# ATmega16U4 register map
Vendor: Atmel; File version: 1.0
CPU: other r0p0, little endian, no MPU, no FPU, 4 interrupt priority bits
Registers are 8-bit, read-write, reset 0x0 unless marked. A register's access mark holds for its fields unless they carry their own. Offsets are from the block's base; [hi:lo] are bit positions.

## TC3 — Timer/Counter, 16-bit
Base 0x00800038
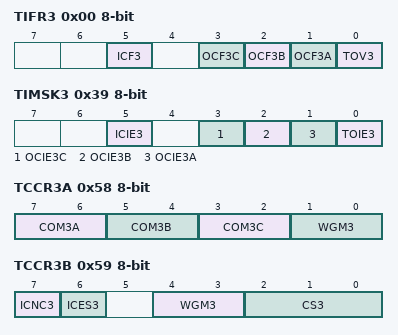
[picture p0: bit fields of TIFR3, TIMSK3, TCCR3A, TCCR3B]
0x00 TIFR3 — Timer/Counter3 Interrupt Flag register (read-only for debugger)
  [5] ICF3 — Input Capture Flag 3
  [3] OCF3C — Output Compare Flag 3C
  [2] OCF3B — Output Compare Flag 3B
  [1] OCF3A — Output Compare Flag 3A
  [0] TOV3 — Timer/Counter3 Overflow Flag
0x39 TIMSK3 — Timer/Counter3 Interrupt Mask Register
  [5] ICIE3 — Timer/Counter3 Input Capture Interrupt Enable
  [3] OCIE3C — Timer/Counter3 Output Compare C Match Interrupt Enable
  [2] OCIE3B — Timer/Counter3 Output Compare B Match Interrupt Enable
  [1] OCIE3A — Timer/Counter3 Output Compare A Match Interrupt Enable
  [0] TOIE3 — Timer/Counter3 Overflow Interrupt Enable
0x58 TCCR3A — Timer/Counter3 Control Register A
  [7:6] COM3A — Compare Output Mode 1A, bits
  [5:4] COM3B — Compare Output Mode 3B, bits
  [3:2] COM3C — Compare Output Mode 3C, bits
  [1:0] WGM3 — Waveform Generation Mode
0x59 TCCR3B — Timer/Counter3 Control Register B
  [7] ICNC3 — Input Capture 3 Noise Canceler
  [6] ICES3 — Input Capture 3 Edge Select
  [4:3] WGM3 — Waveform Generation Mode
  [2:0] CS3 — Prescaler source of Timer/Counter 3
    0=NO_CLOCK_SOURCE_STOPPED; 1=RUNNING_NO_PRESCALING; 2=RUNNING_CLK_8; 3=RUNNING_CLK_64; 4=RUNNING_CLK_256; 5=RUNNING_CLK_1024; 6=RUNNING_EXTCLK_TN_FALLING_EDGE; 7=RUNNING_EXTCLK_TN_RISING_EDGE
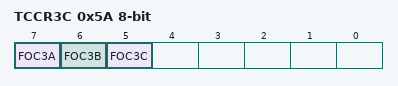
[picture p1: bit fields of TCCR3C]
0x5A TCCR3C — Timer/Counter 3 Control Register C
  [7] FOC3A — Force Output Compare 3A
  [6] FOC3B — Force Output Compare 3B
  [5] FOC3C — Force Output Compare 3C
0x5C TCNT3 16-bit (reset mask 0xFF) — Timer/Counter3 Bytes
  [15:0] TCNT3 — Timer/Counter3 bits
0x5E ICR3 16-bit (reset mask 0xFF) — Timer/Counter3 Input Capture Register Bytes
  [15:0] ICR3 — Timer/Counter3 Input Capture bits
0x60 OCR3A 16-bit (reset mask 0xFF) — Timer/Counter3 Output Compare Register A Bytes
  [15:0] OCR3A — Timer/Counter3 Output Compare A bits
0x62 OCR3B 16-bit (reset mask 0xFF) — Timer/Counter3 Output Compare Register B Bytes
  [15:0] OCR3B — Timer/Counter3 Output Compare B bits
0x64 OCR3C 16-bit (reset mask 0xFF) — Timer/Counter3 Output Compare Register C Bytes
  [15:0] OCR3C — Timer/Counter3 Output Compare C bits

## TC4 — Timer/Counter, 10-bit
Base 0x00800039
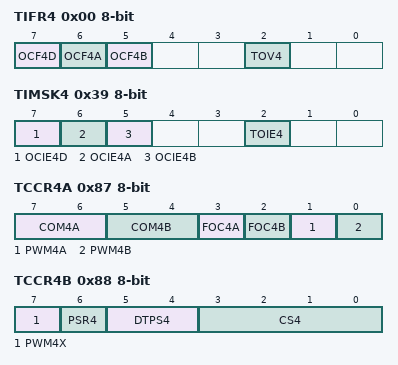
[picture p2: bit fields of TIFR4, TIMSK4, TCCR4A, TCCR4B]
0x00 TIFR4 — Timer/Counter4 Interrupt Flag register (read-only for debugger)
  [7] OCF4D — Output Compare Flag 4D
  [6] OCF4A — Output Compare Flag 4A
  [5] OCF4B — Output Compare Flag 4B
  [2] TOV4 — Timer/Counter4 Overflow Flag
0x39 TIMSK4 — Timer/Counter4 Interrupt Mask Register
  [7] OCIE4D — Timer/Counter4 Output Compare D Match Interrupt Enable
  [6] OCIE4A — Timer/Counter4 Output Compare A Match Interrupt Enable
  [5] OCIE4B — Timer/Counter4 Output Compare B Match Interrupt Enable
  [2] TOIE4 — Timer/Counter4 Overflow Interrupt Enable
0x85 TCNT4 — Timer/Counter4 Low Bytes
  [7:0] TC4 — Timer/Counter4 bits
0x86 TC4H — Timer/Counter4
  [2:0] TC4 — Timer/Counter4 bits
0x87 TCCR4A — Timer/Counter4 Control Register A
  [7:6] COM4A — Compare Output Mode 1A, bits
  [5:4] COM4B — Compare Output Mode 4B, bits
  [3] FOC4A — Force Output Compare Match 4A
  [2] FOC4B — Force Output Compare Match 4B
  [1] PWM4A
  [0] PWM4B
0x88 TCCR4B — Timer/Counter4 Control Register B
  [7] PWM4X — PWM Inversion Mode
  [6] PSR4 — Prescaler Reset Timer/Counter 4
  [5:4] DTPS4 — Dead Time Prescaler Bits
  [3:0] CS4 — Clock Select Bits
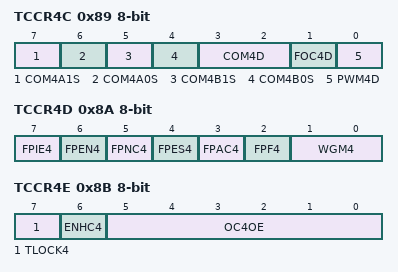
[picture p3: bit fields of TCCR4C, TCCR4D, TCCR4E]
0x89 TCCR4C — Timer/Counter 4 Control Register C
  [7] COM4A1S — Comparator A Output Mode
  [6] COM4A0S — Comparator A Output Mode
  [5] COM4B1S — Comparator B Output Mode
  [4] COM4B0S — Comparator B Output Mode
  [3:2] COM4D — Comparator D Output Mode
  [1] FOC4D — Force Output Compare Match 4D
  [0] PWM4D — Pulse Width Modulator D Enable
0x8A TCCR4D — Timer/Counter 4 Control Register D
  [7] FPIE4 — Fault Protection Interrupt Enable
  [6] FPEN4 — Fault Protection Mode Enable
  [5] FPNC4 — Fault Protection Noise Canceler
  [4] FPES4 — Fault Protection Edge Select
  [3] FPAC4 — Fault Protection Analog Comparator Enable
  [2] FPF4 — Fault Protection Interrupt Flag
  [1:0] WGM4 — Waveform Generation Mode bits
0x8B TCCR4E — Timer/Counter 4 Control Register E
  [7] TLOCK4 — Register Update Lock
  [6] ENHC4 — Enhanced Compare/PWM Mode
  [5:0] OC4OE — Output Compare Override Enable bit
0x96 OCR4A — Timer/Counter4 Output Compare Register A
  [7:0] OCR4A — Timer/Counter4 Output Compare A bits
0x97 OCR4B — Timer/Counter4 Output Compare Register B
  [7:0] OCR4B — Timer/Counter4 Output Compare B bits
0x98 OCR4C — Timer/Counter4 Output Compare Register C
  [7:0] OCR4C — Timer/Counter4 Output Compare C bits
0x99 OCR4D — Timer/Counter4 Output Compare Register D
  [7:0] OCR4D — Timer/Counter4 Output Compare D bits
0x9B DT4 — Timer/Counter 4 Dead Time Value
  [7:0] DT4L — Timer/Counter 4 Dead Time Value Bits
